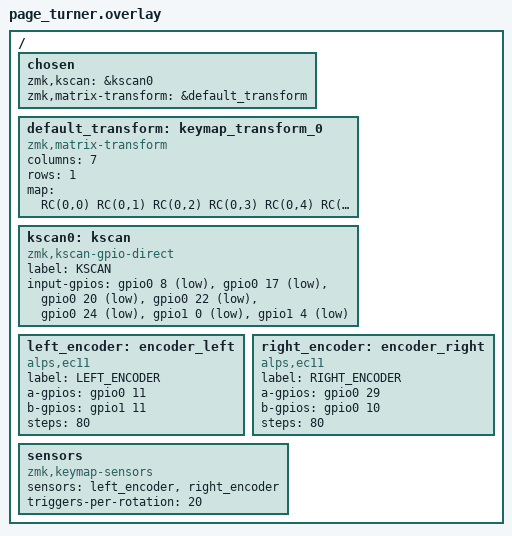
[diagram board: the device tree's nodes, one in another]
/*
 * ProMicro NRF52840 — Page Turner Shield
 * Breadboard prototype layout
 *
 * Pin labels on this board ARE the GPIO numbers directly.
 * e.g. the pad labelled "008" = P0.08, "100" = P1.00, "111" = P1.11
 *
 * WIRING GUIDE
 * ────────────────────────────────────────────────────────────
 *  Board label │ GPIO    │ Column │ Function
 * ─────────────┼─────────┼────────┼────────────────────────────
 *  008          │ P0.08  │ LEFT   │ BTN1 — Next Page   (→)
 *  017          │ P0.17  │ LEFT   │ BTN2 — Prev Page   (←)
 *  020          │ P0.20  │ LEFT   │ BTN3 — Up
 *  022          │ P0.22  │ LEFT   │ BTN4 — Down
 *  024          │ P0.24  │ LEFT   │ BTN5 — Select / hold = BT layer
 *  100          │ P1.00  │ LEFT   │ ENC1 SW — Encoder 1 click
 *  104          │ P1.04  │ LEFT   │ ENC2 SW — Encoder 2 click
 *  011          │ P0.11  │ LEFT   │ ENC1 A  — Encoder 1 phase A
 *  111          │ P1.11  │ RIGHT  │ ENC1 B  — Encoder 1 phase B  ← fixed
 *  029          │ P0.29  │ RIGHT  │ ENC2 A  — Encoder 2 phase A  ← fixed
 *  010          │ P0.10  │ RIGHT  │ ENC2 B  — Encoder 2 phase B
 *  GND          │ GND    │ either │ All button/encoder common ground
 * ────────────────────────────────────────────────────────────
 *
 * All pins are on the main through-hole rows — no underside pads needed.
 *
 * All buttons: one leg → pin, other leg → GND  (internal pull-up used)
 * EC11 encoders:  A → pin,  B → pin,  common → GND,  SW → pin + GND
 *
 * Tip: pins 031, 002, 115, 113, 006 are free for future use / extra buttons.
 *
 * Adjust pin numbers below if you rewire on the breadboard.
 */

#include <dt-bindings/zmk/matrix_transform.h>

/ {
    /* ── Tell ZMK which kscan device and transform to use ── */
    chosen {
        zmk,kscan = &kscan0;
        zmk,matrix-transform = &default_transform;
    };

    /* ── 1 row × 7 columns: maps each direct-GPIO key to RC(row, col) ── */
    default_transform: keymap_transform_0 {
        compatible = "zmk,matrix-transform";
        columns = <7>;
        rows = <1>;
        map = <
            RC(0,0) RC(0,1) RC(0,2) RC(0,3) RC(0,4) RC(0,5) RC(0,6)
        >;
    };

    /* ── 7 direct-GPIO keys (5 buttons + 2 encoder switches) ── */
    kscan0: kscan {
        compatible = "zmk,kscan-gpio-direct";
        label = "KSCAN";

        input-gpios
            = <&gpio0  8 (GPIO_ACTIVE_LOW | GPIO_PULL_UP)>  /* 008 — BTN1 Next Page  */
            , <&gpio0 17 (GPIO_ACTIVE_LOW | GPIO_PULL_UP)>  /* 017 — BTN2 Prev Page  */
            , <&gpio0 20 (GPIO_ACTIVE_LOW | GPIO_PULL_UP)>  /* 020 — BTN3 Up         */
            , <&gpio0 22 (GPIO_ACTIVE_LOW | GPIO_PULL_UP)>  /* 022 — BTN4 Down       */
            , <&gpio0 24 (GPIO_ACTIVE_LOW | GPIO_PULL_UP)>  /* 024 — BTN5 Select     */
            , <&gpio1  0 (GPIO_ACTIVE_LOW | GPIO_PULL_UP)>  /* 100 — ENC1 Switch     */
            , <&gpio1  4 (GPIO_ACTIVE_LOW | GPIO_PULL_UP)>  /* 104 — ENC2 Switch     */
            ;
    };

    /* ── EC11 Encoder 1 — primary page turner ── */
    left_encoder: encoder_left {
        compatible = "alps,ec11";
        label = "LEFT_ENCODER";
        a-gpios = <&gpio0 11 (GPIO_ACTIVE_HIGH | GPIO_PULL_UP)>;  /* 011 — left col  */
        b-gpios = <&gpio1 11 (GPIO_ACTIVE_HIGH | GPIO_PULL_UP)>;  /* 111 — right col */
        steps = <80>;   /* 20 detents × 4 = 80; tune for your knob */
        status = "okay";
    };

    /* ── EC11 Encoder 2 — secondary (scroll / chapter jump) ── */
    right_encoder: encoder_right {
        compatible = "alps,ec11";
        label = "RIGHT_ENCODER";
        a-gpios = <&gpio0 29 (GPIO_ACTIVE_HIGH | GPIO_PULL_UP)>;  /* 029 — right col */
        b-gpios = <&gpio0 10 (GPIO_ACTIVE_HIGH | GPIO_PULL_UP)>;  /* 010 — right col */
        steps = <80>;
        status = "okay";
    };

    /* ── Expose both encoders to ZMK ── */
    sensors: sensors {
        compatible = "zmk,keymap-sensors";
        sensors = <&left_encoder &right_encoder>;
        triggers-per-rotation = <20>;  /* lower = faster, higher = finer */
    };
};
